# STM32WLE4C8U6 register map
File version: 1.0
Registers are 32-bit, access not given, reset 0x0 unless marked. A register's access mark holds for its fields unless they carry their own. Offsets are from the block's base; [hi:lo] are bit positions; {n}, {i} and the like mark numbered series.

## LPUART1
Base 0x40008000
0x00 CR1FIFO_EN
  [31] RXFFIE, [30] TXFEIE, [29] FIFOEN, [28] M1, [25:21] DEAT, [20:16] DEDT, [27:15] s, [14] CMIE, [13] MME, [12] M0, [11] WAKE, [10] PCE, [9] PS, [8] PEIE, [7] TXFNFIE, [6] TCIE, [5] RXFNEIE, [4] IDLEIE, [3] TE, [2] RE, [1] UESM, [0] UE
0x00 CR1FIFO_DIS
  [29] FIFOEN, [28] M1, [25:21] DEAT, [20:16] DEDT, [31:15] s, [14] CMIE, [13] MME, [12] M0, [11] WAKE, [10] PCE, [9] PS, [8] PEIE, [7] TXEIE, [6] TCIE, [5] RXNEIE, [4] IDLEIE, [3] TE, [2] RE, [1] UESM, [0] UE
0x04 CR2
  [31:24] ADD, [19] MSBFIRST, [18] DATAINV, [17] TXINV, [16] RXINV, [15] SWAP, [13:12] STOP, [4] ADDM7, [23:0] s
0x08 CR3
  [31:29] TXFTCFG, [28] RXFTIE, [27:25] RXFTCFG, [23] TXFTIE, [22] WUFIE, [21:20] WUS, [15] DEP, [14] DEM, [13] DDRE, [12] OVRDIS, [10] CTSIE, [9] CTSE, [8] RTSE, [7] DMAT, [6] DMAR, [3] HDSEL, [24:1] s, [0] EIE
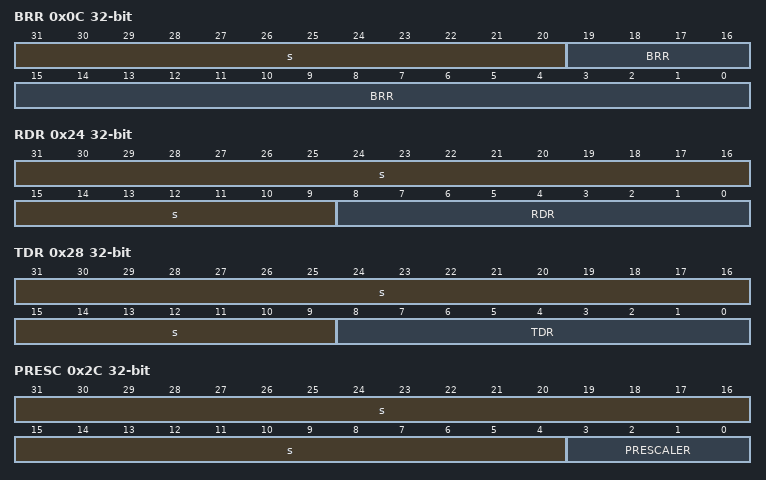
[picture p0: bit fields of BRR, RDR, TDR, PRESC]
0x0C BRR
  [31:20] s, [19:0] BRR
0x18 RQR
  [4] TXFRQ, [3] RXFRQ, [2] MMRQ, [1] SBKRQ, [31:0] s
0x1C ISRFIFO_EN
  [27] TXFT, [26] RXFT, [24] RXFF, [23] TXFF, [22] REACK, [21] TEACK, [20] WUF, [19] RWU, [18] SBKF, [17] CMF, [16] BUSY, [10] CTS, [9] CTSIF, [31:8] s, [7] TXFNF, [6] TC, [5] RXFNE, [4] IDLE, [3] ORE, [2] NE, [1] FE, [0] PE
0x1C ISRFIFO_DIS
  [22] REACK, [21] TEACK, [20] WUF, [19] RWU, [18] SBKF, [17] CMF, [16] BUSY, [10] CTS, [9] CTSIF, [31:8] s, [7] TXE, [6] TC, [5] RXNE, [4] IDLE, [3] ORE, [2] NE, [1] FE, [0] PE
0x20 ICR
  [20] WUCF, [17] CMCF, [9] CTSCF, [6] TCCF, [31:5] s, [4] IDLECF, [3] ORECF, [2] NECF, [1] FECF, [0] PECF
0x24 RDR
  [31:9] s, [8:0] RDR
0x28 TDR
  [31:9] s, [8:0] TDR
0x2C PRESC
  [31:4] s, [3:0] PRESCALER

## LPTIM3
Base 0x40009800
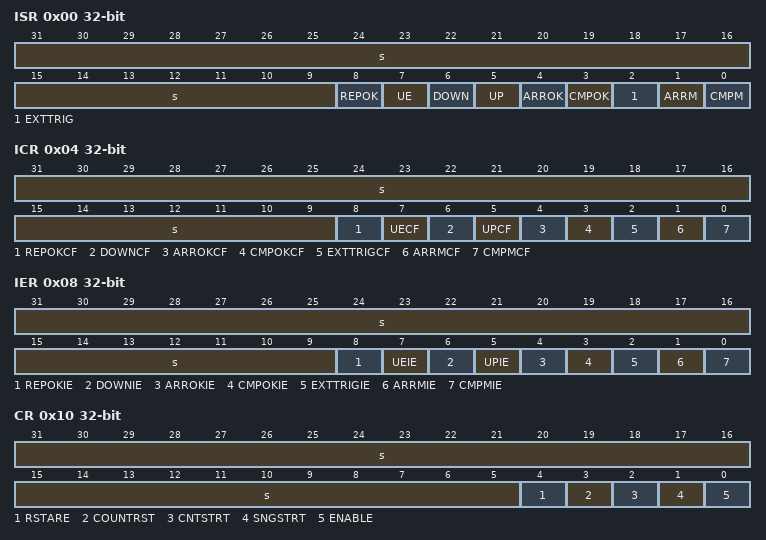
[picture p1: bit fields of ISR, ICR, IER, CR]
0x00 ISR
  [31:9] s, [8] REPOK, [7] UE, [6] DOWN, [5] UP, [4] ARROK, [3] CMPOK, [2] EXTTRIG, [1] ARRM, [0] CMPM
0x04 ICR
  [31:9] s, [8] REPOKCF, [7] UECF, [6] DOWNCF, [5] UPCF, [4] ARROKCF, [3] CMPOKCF, [2] EXTTRIGCF, [1] ARRMCF, [0] CMPMCF
0x08 IER
  [31:9] s, [8] REPOKIE, [7] UEIE, [6] DOWNIE, [5] UPIE, [4] ARROKIE, [3] CMPOKIE, [2] EXTTRIGIE, [1] ARRMIE, [0] CMPMIE
0x0C CFGR
  [24] ENC, [23] COUNTMODE, [22] PRELOAD, [21] WAVPOL, [20] WAVE, [19] TIMOUT, [18:17] TRIGEN, [15:13] TRIGSEL, [11:9] PRESC, [7:6] TRGFLT, [31:5] s, [4:3] CKFLT, [2:1] CKPOL, [0] CKSEL
0x10 CR
  [31:5] s, [4] RSTARE, [3] COUNTRST, [2] CNTSTRT, [1] SNGSTRT, [0] ENABLE
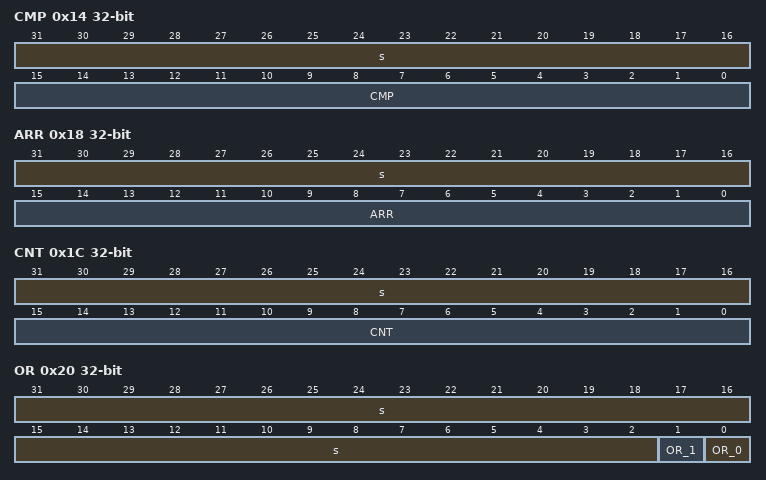
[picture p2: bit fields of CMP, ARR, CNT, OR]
0x14 CMP
  [31:16] s, [15:0] CMP
0x18 ARR
  [31:16] s, [15:0] ARR
0x1C CNT
  [31:16] s, [15:0] CNT
0x20 OR
  [31:2] s, [1] OR_1, [0] OR_0
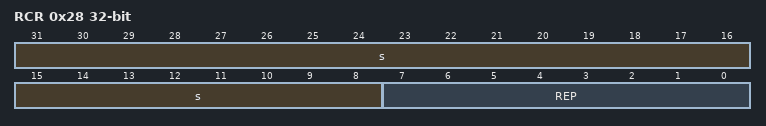
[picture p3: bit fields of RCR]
0x28 RCR
  [31:8] s, [7:0] REP

## TAMP
Base 0x4000B000
0x00 CR1
  [23] ITAMP8E, [21] ITAMP6E, [20] ITAMP5E, [18] ITAMP3E, [31:3] s, [2] TAMP3E, [1] TAMP2E, [0] TAMP1E
0x04 CR2
  [26] TAMP3TRG, [25] TAMP2TRG, [24] TAMP1TRG, [23] BKERASE, [18] TAMP3MSK, [17] TAMP2MSK, [16] TAMP1MSK, [31:3] s, [2] TAMP3NOER, [1] TAMP2NOER, [0] TAMP1NOER
0x08 CR3
  [7] ITAMP8NOER, [5] ITAMP6NOER, [4] ITAMP5NOER, [2] ITAMP3NOER, [31:0] s
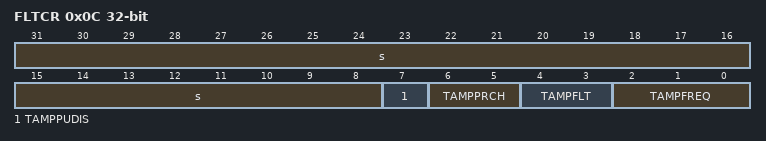
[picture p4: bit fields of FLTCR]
0x0C FLTCR
  [31:8] s, [7] TAMPPUDIS, [6:5] TAMPPRCH, [4:3] TAMPFLT, [2:0] TAMPFREQ
0x2C IER
  [23] ITAMP8IE, [21] ITAMP6IE, [20] ITAMP5IE, [18] ITAMP3IE, [31:3] s, [2] TAMP3IE, [1] TAMP2IE, [0] TAMP1IE
0x30 SR
  [23] ITAMP8F, [21] ITAMP6F, [20] ITAMP5F, [18] ITAMP3F, [31:3] s, [2] TAMP3F, [1] TAMP2F, [0] TAMP1F
0x34 MISR
  [23] ITAMP8MF, [21] ITAMP6MF, [20] ITAMP5MF, [18] ITAMP3MF, [31:3] s, [2] TAMP3MF, [1] TAMP2MF, [0] TAMP1MF
0x3C SCR
  [23] CITAMP8F, [21] CITAMP6F, [20] CITAMP5F, [18] CITAMP3F, [31:3] s, [2] CTAMP3F, [1] CTAMP2F, [0] CTAMP1F
0x40 COUNTR
  [31:0] COUNT
{0x100+4i} BKP{i}R (i=0..19)
  [31:0] BKP

## SYSCFG
Base 0x40010000
Same registers: SYSCFG 0x40010100, SYSCFG 0x40010100
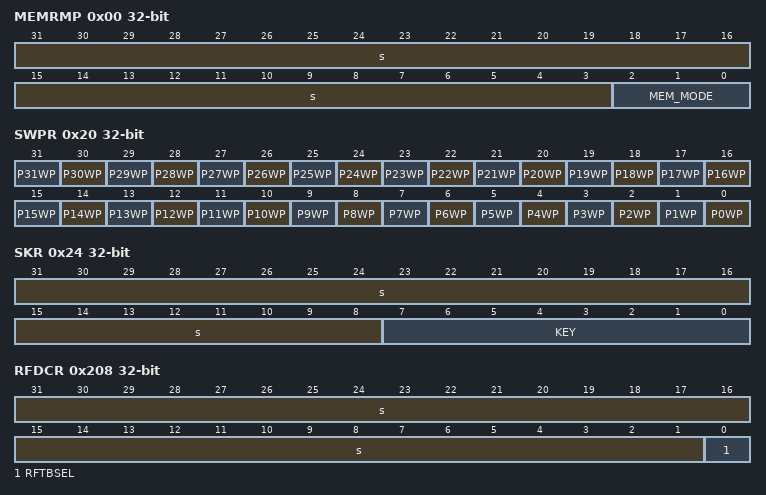
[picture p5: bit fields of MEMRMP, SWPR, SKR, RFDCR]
0x00 MEMRMP
  [31:3] s, [2:0] MEM_MODE
0x04 CFGR1
  [22] I2C3_FMP, [21] I2C2_FMP, [20] I2C1_FMP, [n+10] I2C_PB{n}_FMP (n=6..9), [8] BOOSTEN, [31:0] s
0x08 EXTICR1
  [4n+2:4n] EXTI{n} (n=0..3), [31:3] s
0x0C EXTICR2
  [4n-14:4n-16] EXTI{n} (n=4..7), [31:3] s
0x10 EXTICR3
  [4n-30:4n-32] EXTI{n} (n=8..11), [31:3] s
0x14 EXTICR4
  [4n-46:4n-48] EXTI{n} (n=12..15), [31:3] s
0x18 SCSR
  [8] PKASRAMBSY, [31:2] s, [1] SRAMBSY, [0] SRAM2ER
0x1C CFGR2
  [8] SPF, [31:4] s, [3] ECCL, [2] PVDL, [1] SPL, [0] CLL
0x20 SWPR
  [n] P{n}WP (n=0..31)
0x24 SKR
  [31:8] s, [7:0] KEY
0x208 RFDCR
  [31:1] s, [0] RFTBSEL
